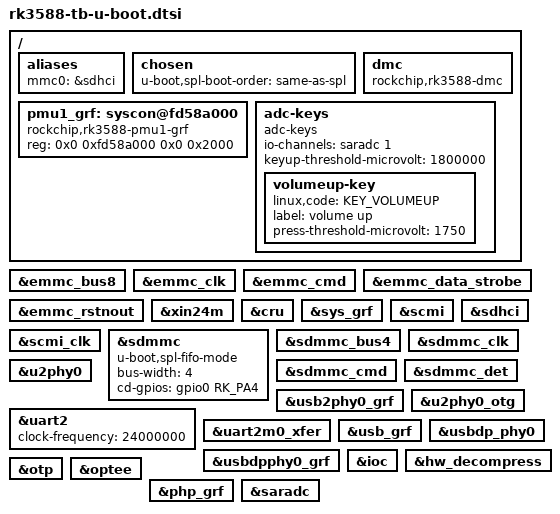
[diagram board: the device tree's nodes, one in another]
// SPDX-License-Identifier: (GPL-2.0+ OR MIT)
/*
 * Copyright (c) 2026 Rockchip Electronics Co., Ltd.
 */

#include "rockchip-u-boot.dtsi"
#include <dt-bindings/phy/phy.h>
#include <dt-bindings/input/input.h>

/ {
	aliases {
		mmc0 = &sdhci;
	};

	chosen {
		u-boot,spl-boot-order = "same-as-spl", &sdmmc;
	};

	dmc {
		compatible = "rockchip,rk3588-dmc";
		bootph-all;
		status = "okay";
	};

	pmu1_grf: syscon@fd58a000 {
		bootph-all;
		compatible = "rockchip,rk3588-pmu1-grf", "syscon";
		reg = <0x0 0xfd58a000 0x0 0x2000>;
	};

	adc-keys {
		compatible = "adc-keys";
		io-channels = <&saradc 1>;
		io-channel-names = "buttons";
		keyup-threshold-microvolt = <1800000>;
		bootph-all;
		status = "okay";

		volumeup-key {
			bootph-all;
			linux,code = <KEY_VOLUMEUP>;
			label = "volume up";
			press-threshold-microvolt = <1750>;
		};
	};
};

&emmc_bus8 {
	bootph-all;
};

&emmc_clk {
	bootph-all;
};

&emmc_cmd {
	bootph-all;
};

&emmc_data_strobe {
	bootph-all;
};

&emmc_rstnout {
	bootph-all;
};

&xin24m {
	bootph-all;
	status = "okay";
};

&cru {
	bootph-all;
	status = "okay";
};

&sys_grf {
	bootph-pre-ram;
	status = "okay";
};

&scmi {
	bootph-all;
};

&scmi_clk {
	bootph-all;
};

&sdmmc {
	bootph-all;
	u-boot,spl-fifo-mode;
	bus-width = <4>;
	cd-gpios = <&gpio0 RK_PA4 GPIO_ACTIVE_HIGH>;
	status = "okay";
};

&sdhci {
	bootph-all;
};

&sdmmc_bus4 {
	bootph-all;
	status = "okay";
};

&sdmmc_clk {
	bootph-all;
	status = "okay";
};

&sdmmc_cmd {
	bootph-all;
	status = "okay";
};

&sdmmc_det {
	bootph-all;
	status = "okay";
};

&usb2phy0_grf {
	bootph-all;
};

&u2phy0 {
	bootph-all;
	status = "okay";
};

&u2phy0_otg {
	bootph-all;
	status = "okay";
};

&uart2 {
	clock-frequency = <24000000>;
	bootph-pre-ram;
	status = "okay";
};

&uart2m0_xfer {
	bootph-all;
};

&usb_grf{
	bootph-all;
};

&usbdpphy0_grf{
	bootph-all;
};

&usbdp_phy0{
	bootph-all;
	status = "okay";
};

&ioc {
	bootph-pre-ram;
};

&hw_decompress {
	bootph-all;
	status = "okay";
};

&otp {
	bootph-all;
	status = "okay";
};

&optee {
	bootph-all;
	status = "okay";
};

&php_grf {
	bootph-all;
};

&saradc {
	bootph-all;
	status = "okay";
};
